# DCC0 register map
Vendor: Texas Instruments
Peripheral module from a debugger description file (folder J7VCL).
Registers are 32-bit, read-write, reset 0x0 unless marked. A register's access mark holds for its fields unless they carry their own. Offsets are as the file gives them; lines under a group give offsets from that group; [hi:lo] are bit positions; {n}, {i} and the like mark numbered series; 'fields as' and 'values as' point back to an identical list; <NAME> marks a mode.

## DCC0
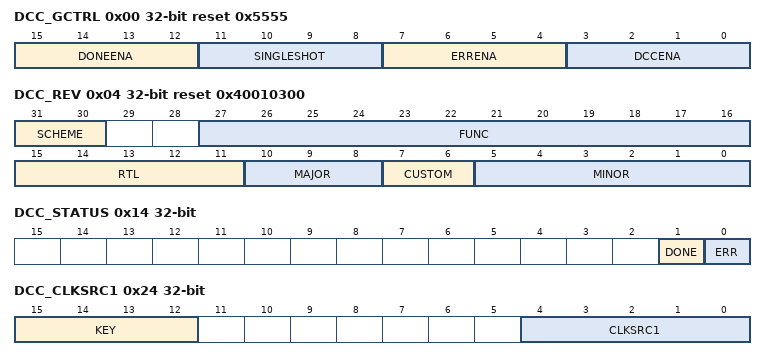
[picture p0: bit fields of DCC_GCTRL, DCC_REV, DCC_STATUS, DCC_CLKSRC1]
0x00 DCC_GCTRL reset 0x5555 — Starts / stops the counters. Clears the error signal.
  [15:12] DONEENA — The DONEENA bit enables/disables the done interrupt signal, but has no effect on the done status flag in DCC_STAT register.
  [11:8] SINGLESHOT — The SINGLESHOT bit enables/disables repetitive operation of the DCC.
  [7:4] ERRENA — The ERRENA bit enables/disables the error signal.
  [3:0] DCCENA — The DCCENA bit starts and stops the operation of the dcc.
0x04 DCC_REV ro reset 0x40010300 — Specifies the module version.
  [31:30] SCHEME — User, privilege, and debug mode (read): Returns 01.
  [27:16] FUNC — Reflects software-compatability.
  [15:11] RTL — Incremented for releases due to spec changes or post-release design changes.
  [10:8] MAJOR — Represents major changes to the module (e.g.
  [7:6] CUSTOM — Indicates a special version of the module.
  [5:0] MINOR — Represents minor changes to the module (e.g.
0x08 DCC_CNTSEED0 — Seed value for the counter attached to clock source 0
  [19:0] COUNTSEED0 — This field contains the seed value that gets loaded into counter 0 (clock source 0).
0x0C DCC_VALIDSEED0 — Seed value for the timeout counter attached to clock source 0.
  [15:0] VALIDSEED0 — This field contains the seed value that gets loaded into the valid duration counter for clock source 0.
0x10 DCC_CNTSEED1 — Seed value for the counter attached to clock source 1.
  [19:0] COUNTSEED1 — This field contains the seed value that gets loaded into counter 1 (clock source 1).
0x14 DCC_STATUS access not given — Specifies the status of the DCC Module.
  [1] DONE — Indicates when single-shot mode is complete without error. (access RW1C)
  [0] ERR — Indicates whether or not an error has occured. (access RW1C)
0x18 DCC_CNT0 ro — Value of the counter attached to clock source 0.
  [19:0] COUNT0 — This field contains the current value of counter 0.
0x1C DCC_VALID0 ro — Value of the valid counter attached to clock source 0.
  [15:0] VALID0 — This field contains the current value of valid counter 0.
0x20 DCC_CNT1 ro — Value of the counter attached to clock source 1.
  [19:0] COUNT1 — This field contains the current value of counter 1.
0x24 DCC_CLKSRC1 — Selects the clock source for counter 1.
  [15:12] KEY — This field enables or disables clock source selection for counter 1.
  [4:0] CLKSRC1 — This field specifies the clock source for counter 1, when the KEY field enables this feature.
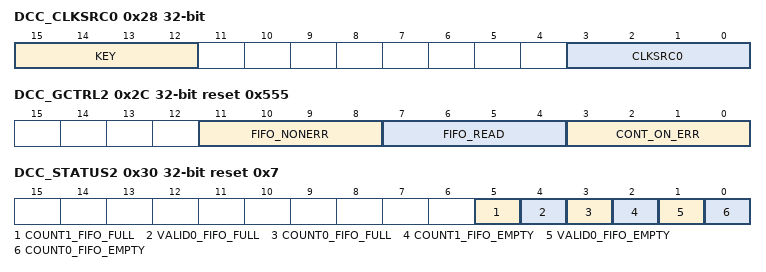
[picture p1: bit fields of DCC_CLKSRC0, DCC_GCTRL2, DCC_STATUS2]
0x28 DCC_CLKSRC0 — Selects the clock source for counter 0.
  [15:12] KEY — This field enables or disables clock source selection for counter 0.
  [3:0] CLKSRC0 — This field specifies the clock source for counter 0.
0x2C DCC_GCTRL2 reset 0x555 — Allows configuring different modes of operation for DCC.
  [11:8] FIFO_NONERR — Enables/disables FIFO writes without the error event on completion of comparison window.
  [7:4] FIFO_READ — Enables the counter read registers reflect FIFO output instead of the live counter value.
  [3:0] CONT_ON_ERR — Continues to next window of comparison despite the error condition.
0x30 DCC_STATUS2 ro reset 0x7 — Specifies the status of the DCC FIFOs.
  [5] COUNT1_FIFO_FULL, [4] VALID0_FIFO_FULL, [3] COUNT0_FIFO_FULL, [2] COUNT1_FIFO_EMPTY, [1] VALID0_FIFO_EMPTY, [0] COUNT0_FIFO_EMPTY
0x34 DCC_ERRCNT — Counts number of errors since last clear.
  [9:0] ERRCNT — Counts the number of errors after the last write to this register or reset.
